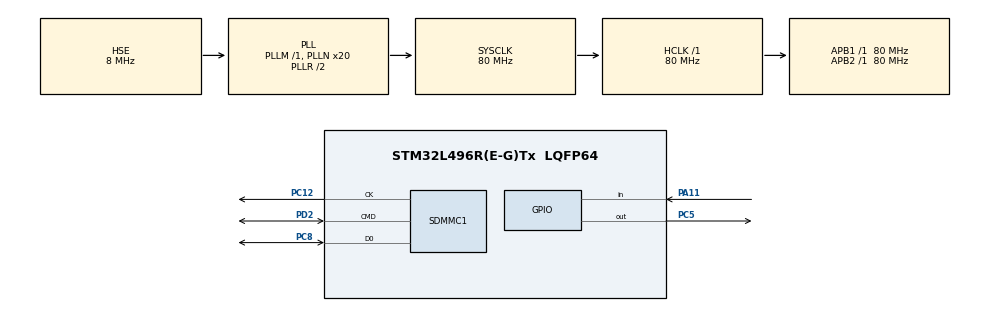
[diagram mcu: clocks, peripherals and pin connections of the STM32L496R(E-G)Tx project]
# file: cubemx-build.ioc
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FATFS.BSP.number=1
FATFS._FS_EXFAT=1
FATFS._USE_LFN=2
FATFS0.BSP.STBoard=false
FATFS0.BSP.api=Unknown
FATFS0.BSP.i2caddr=0
FATFS0.BSP.instance=PA11
FATFS0.BSP.ip=GPIO
FATFS0.BSP.mode=Input
FATFS0.BSP.name=Detect_SDIO
FATFS0.BSP.solution=PA11
Mcu.Family=STM32L4
Mcu.Name=STM32L496R(E-G)Tx
Mcu.Package=LQFP64
NVIC.PriorityGroup=NVIC_PRIORITYGROUP_4
PA11.GPIO_PuPd=GPIO_PULLDOWN
PA11.Signal=GPIO_Input
PA13\ (JTMS/SWDIO).Mode=Serial_Wire
PA13\ (JTMS/SWDIO).Signal=SYS_JTMS-SWDIO
PA14\ (JTCK/SWCLK).Mode=Serial_Wire
PA14\ (JTCK/SWCLK).Signal=SYS_JTCK-SWCLK
PC12.Mode=SD_1_bit
PC12.Signal=SDMMC1_CK
PC5.Signal=GPIO_Output
PC8.Mode=SD_1_bit
PC8.Signal=SDMMC1_D0
PD2.Mode=SD_1_bit
PD2.Signal=SDMMC1_CMD
PH0-OSC_IN\ (PH0).Mode=HSE-External-Oscillator
PH0-OSC_IN\ (PH0).Signal=RCC_OSC_IN
PH1-OSC_OUT\ (PH1).Mode=HSE-External-Oscillator
PH1-OSC_OUT\ (PH1).Signal=RCC_OSC_OUT
ProjectManager.HeapSize=0x200
ProjectManager.StackSize=0x400
ProjectManager.TargetToolchain=Makefile
RCC.ADCFreq_Value=48000000
RCC.AHBFreq_Value=80000000
RCC.APB1Freq_Value=80000000
RCC.APB1TimFreq_Value=80000000
RCC.APB2Freq_Value=80000000
RCC.APB2TimFreq_Value=80000000
RCC.CortexFreq_Value=80000000
RCC.HCLKFreq_Value=80000000
RCC.HSE_VALUE=8000000
RCC.HSI48_VALUE=48000000
RCC.HSI_VALUE=16000000
RCC.LSE_VALUE=32768
RCC.MSI_VALUE=4000000
RCC.PLLN=20
RCC.PLLSAI1N=12
RCC.PLLSAI1Q=RCC_PLLQ_DIV4
RCC.PLLSourceVirtual=RCC_PLLSOURCE_HSE
RCC.SYSCLKFreq_VALUE=80000000
RCC.SYSCLKSource=RCC_SYSCLKSOURCE_PLLCLK
RCC.USBFreq_Value=24000000
RCC.VCOOutputFreq_Value=160000000
VP_FATFS_VS_SDIO.Mode=SDIO
board=custom

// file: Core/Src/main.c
/* USER CODE BEGIN Header */
/**
  ******************************************************************************
  * @file           : main.c
  * @brief          : Main program body
  ******************************************************************************
  * @attention
  *
  * Copyright (c) 2022 STMicroelectronics.
  * All rights reserved.
  *
  * This software is licensed under terms that can be found in the LICENSE file
  * in the root directory of this software component.
  * If no LICENSE file comes with this software, it is provided AS-IS.
  *
  ******************************************************************************
  */
/* USER CODE END Header */
#include "main.h"
#include "fatfs.h"
#include "sdmmc.h"
#include "gpio.h"

/* USER CODE BEGIN Includes */
#include "endo_dev.h"

/* USER CODE END Includes */

void SystemClock_Config(void);

int main(void)
{

  /* MCU Configuration--------------------------------------------------------*/

  /* Reset of all peripherals, Initializes the Flash interface and the Systick. */
  HAL_Init();

  /* Configure the system clock */
  SystemClock_Config();

  /* Initialize all configured peripherals */
  MX_GPIO_Init();
  MX_SDMMC1_SD_Init();
  MX_FATFS_Init();
  /* USER CODE BEGIN 2 */
  sd_test();

  /* USER CODE END 2 */

  /* Infinite loop */
  /* USER CODE BEGIN WHILE */
  while (1)
  {
    flash(1, 100, 100);
    /* USER CODE END WHILE */

  }
}

void SystemClock_Config(void)
{
  RCC_OscInitTypeDef RCC_OscInitStruct = {0};
  RCC_ClkInitTypeDef RCC_ClkInitStruct = {0};

  /** Configure the main internal regulator output voltage
  */
  if (HAL_PWREx_ControlVoltageScaling(PWR_REGULATOR_VOLTAGE_SCALE1) != HAL_OK)
  {
    Error_Handler();
  }

  /** Initializes the RCC Oscillators according to the specified parameters
  * in the RCC_OscInitTypeDef structure.
  */
  RCC_OscInitStruct.OscillatorType = RCC_OSCILLATORTYPE_HSE;
  RCC_OscInitStruct.HSEState = RCC_HSE_ON;
  RCC_OscInitStruct.PLL.PLLState = RCC_PLL_ON;
  RCC_OscInitStruct.PLL.PLLSource = RCC_PLLSOURCE_HSE;
  RCC_OscInitStruct.PLL.PLLM = 1;
  RCC_OscInitStruct.PLL.PLLN = 20;
  RCC_OscInitStruct.PLL.PLLP = RCC_PLLP_DIV2;
  RCC_OscInitStruct.PLL.PLLQ = RCC_PLLQ_DIV2;
  RCC_OscInitStruct.PLL.PLLR = RCC_PLLR_DIV2;
  if (HAL_RCC_OscConfig(&RCC_OscInitStruct) != HAL_OK)
  {
    Error_Handler();
  }

  /** Initializes the CPU, AHB and APB buses clocks
  */
  RCC_ClkInitStruct.ClockType = RCC_CLOCKTYPE_HCLK|RCC_CLOCKTYPE_SYSCLK
                              |RCC_CLOCKTYPE_PCLK1|RCC_CLOCKTYPE_PCLK2;
  RCC_ClkInitStruct.SYSCLKSource = RCC_SYSCLKSOURCE_PLLCLK;
  RCC_ClkInitStruct.AHBCLKDivider = RCC_SYSCLK_DIV1;
  RCC_ClkInitStruct.APB1CLKDivider = RCC_HCLK_DIV1;
  RCC_ClkInitStruct.APB2CLKDivider = RCC_HCLK_DIV1;

  if (HAL_RCC_ClockConfig(&RCC_ClkInitStruct, FLASH_LATENCY_4) != HAL_OK)
  {
    Error_Handler();
  }
}

void Error_Handler(void)
{
  /* USER CODE BEGIN Error_Handler_Debug */
  /* User can add his own implementation to report the HAL error return state */
  __disable_irq();
  while (1) {
    flash(1, 2000, 50);
  }
  /* USER CODE END Error_Handler_Debug */
}
